# PIC32MK0512MCJ048 device description
Architecture: MIPS; Family: PIC32MK; Series: PIC32MK
Registers are 32-bit, read-write, no defined reset value unless marked. A register's access mark holds for its fields unless they carry their own. Offsets are from the block's base; [hi:lo] are bit positions; 'fields as' and 'values as' point back to an identical list.

## GPIO
Instances: GPIO 0x1f860000 in periph_pb4_std
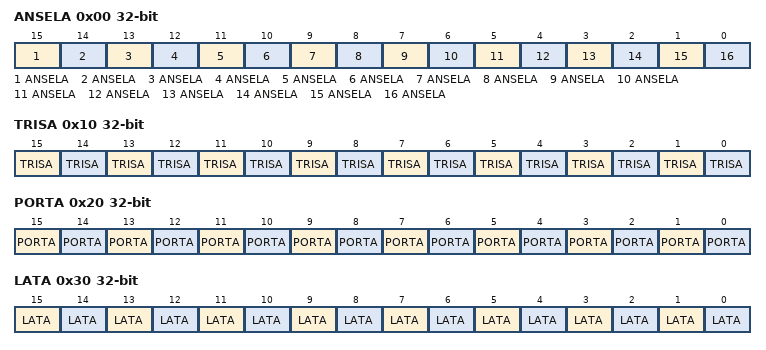
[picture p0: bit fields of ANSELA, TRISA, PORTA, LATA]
0x00 ANSELA
  [15] ANSELA, [14] ANSELA, [13] ANSELA, [12] ANSELA, [11] ANSELA, [10] ANSELA, [9] ANSELA, [8] ANSELA, [7] ANSELA, [6] ANSELA, [5] ANSELA, [4] ANSELA, [3] ANSELA, [2] ANSELA, [1] ANSELA, [0] ANSELA
0x10 TRISA
  [15] TRISA, [14] TRISA, [13] TRISA, [12] TRISA, [11] TRISA, [10] TRISA, [9] TRISA, [8] TRISA, [7] TRISA, [6] TRISA, [5] TRISA, [4] TRISA, [3] TRISA, [2] TRISA, [1] TRISA, [0] TRISA
0x20 PORTA
  [15] PORTA, [14] PORTA, [13] PORTA, [12] PORTA, [11] PORTA, [10] PORTA, [9] PORTA, [8] PORTA, [7] PORTA, [6] PORTA, [5] PORTA, [4] PORTA, [3] PORTA, [2] PORTA, [1] PORTA, [0] PORTA
0x30 LATA
  [15] LATA, [14] LATA, [13] LATA, [12] LATA, [11] LATA, [10] LATA, [9] LATA, [8] LATA, [7] LATA, [6] LATA, [5] LATA, [4] LATA, [3] LATA, [2] LATA, [1] LATA, [0] LATA
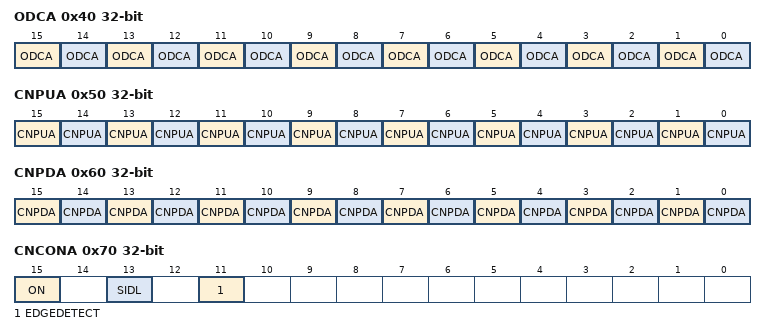
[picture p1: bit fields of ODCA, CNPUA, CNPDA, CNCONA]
0x40 ODCA
  [15] ODCA, [14] ODCA, [13] ODCA, [12] ODCA, [11] ODCA, [10] ODCA, [9] ODCA, [8] ODCA, [7] ODCA, [6] ODCA, [5] ODCA, [4] ODCA, [3] ODCA, [2] ODCA, [1] ODCA, [0] ODCA
0x50 CNPUA
  [15] CNPUA, [14] CNPUA, [13] CNPUA, [12] CNPUA, [11] CNPUA, [10] CNPUA, [9] CNPUA, [8] CNPUA, [7] CNPUA, [6] CNPUA, [5] CNPUA, [4] CNPUA, [3] CNPUA, [2] CNPUA, [1] CNPUA, [0] CNPUA
0x60 CNPDA
  [15] CNPDA, [14] CNPDA, [13] CNPDA, [12] CNPDA, [11] CNPDA, [10] CNPDA, [9] CNPDA, [8] CNPDA, [7] CNPDA, [6] CNPDA, [5] CNPDA, [4] CNPDA, [3] CNPDA, [2] CNPDA, [1] CNPDA, [0] CNPDA
0x70 CNCONA — Change Notice control for PORTx Register
  [15] ON — Change Notice Control ON bit
    1=CN is enabled; 0=CN is disabled
  [13] SIDL
  [11] EDGEDETECT — Change Notification Style bit
    1=Edge Style. Detect edge transitions (CNFx used for CN Event).; 0=Mismatch Style. Detect change from last PORTx read (CNSTATx used for CN Event).
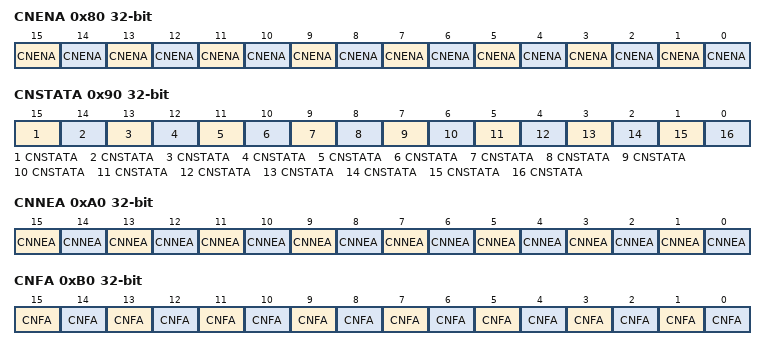
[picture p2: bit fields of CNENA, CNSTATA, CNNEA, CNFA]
0x80 CNENA
  [15] CNENA, [14] CNENA, [13] CNENA, [12] CNENA, [11] CNENA, [10] CNENA, [9] CNENA, [8] CNENA, [7] CNENA, [6] CNENA, [5] CNENA, [4] CNENA, [3] CNENA, [2] CNENA, [1] CNENA, [0] CNENA
0x90 CNSTATA
  [15] CNSTATA, [14] CNSTATA, [13] CNSTATA, [12] CNSTATA, [11] CNSTATA, [10] CNSTATA, [9] CNSTATA, [8] CNSTATA, [7] CNSTATA, [6] CNSTATA, [5] CNSTATA, [4] CNSTATA, [3] CNSTATA, [2] CNSTATA, [1] CNSTATA, [0] CNSTATA
0xA0 CNNEA
  [15] CNNEA, [14] CNNEA, [13] CNNEA, [12] CNNEA, [11] CNNEA, [10] CNNEA, [9] CNNEA, [8] CNNEA, [7] CNNEA, [6] CNNEA, [5] CNNEA, [4] CNNEA, [3] CNNEA, [2] CNNEA, [1] CNNEA, [0] CNNEA
0xB0 CNFA
  [15] CNFA, [14] CNFA, [13] CNFA, [12] CNFA, [11] CNFA, [10] CNFA, [9] CNFA, [8] CNFA, [7] CNFA, [6] CNFA, [5] CNFA, [4] CNFA, [3] CNFA, [2] CNFA, [1] CNFA, [0] CNFA
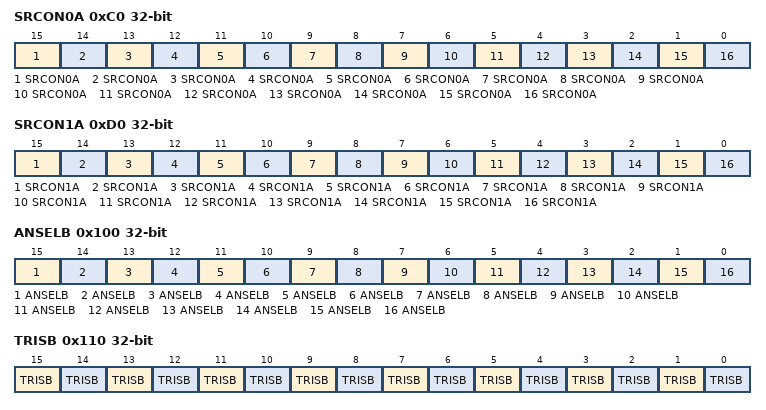
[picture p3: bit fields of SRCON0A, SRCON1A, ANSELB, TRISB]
0xC0 SRCON0A
  [15] SRCON0A, [14] SRCON0A, [13] SRCON0A, [12] SRCON0A, [11] SRCON0A, [10] SRCON0A, [9] SRCON0A, [8] SRCON0A, [7] SRCON0A, [6] SRCON0A, [5] SRCON0A, [4] SRCON0A, [3] SRCON0A, [2] SRCON0A, [1] SRCON0A, [0] SRCON0A
0xD0 SRCON1A
  [15] SRCON1A, [14] SRCON1A, [13] SRCON1A, [12] SRCON1A, [11] SRCON1A, [10] SRCON1A, [9] SRCON1A, [8] SRCON1A, [7] SRCON1A, [6] SRCON1A, [5] SRCON1A, [4] SRCON1A, [3] SRCON1A, [2] SRCON1A, [1] SRCON1A, [0] SRCON1A
0x100 ANSELB
  [15] ANSELB, [14] ANSELB, [13] ANSELB, [12] ANSELB, [11] ANSELB, [10] ANSELB, [9] ANSELB, [8] ANSELB, [7] ANSELB, [6] ANSELB, [5] ANSELB, [4] ANSELB, [3] ANSELB, [2] ANSELB, [1] ANSELB, [0] ANSELB
0x110 TRISB
  [15] TRISB, [14] TRISB, [13] TRISB, [12] TRISB, [11] TRISB, [10] TRISB, [9] TRISB, [8] TRISB, [7] TRISB, [6] TRISB, [5] TRISB, [4] TRISB, [3] TRISB, [2] TRISB, [1] TRISB, [0] TRISB
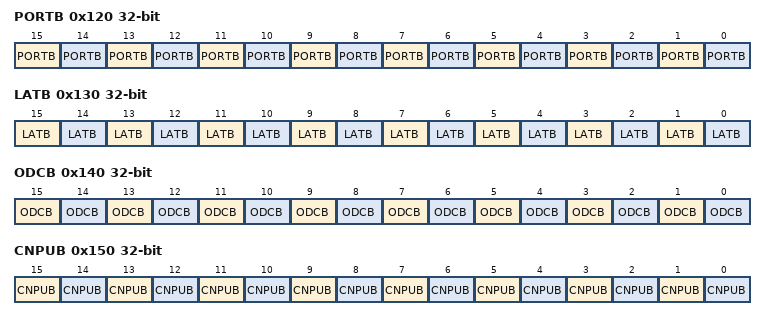
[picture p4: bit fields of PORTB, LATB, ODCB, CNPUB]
0x120 PORTB
  [15] PORTB, [14] PORTB, [13] PORTB, [12] PORTB, [11] PORTB, [10] PORTB, [9] PORTB, [8] PORTB, [7] PORTB, [6] PORTB, [5] PORTB, [4] PORTB, [3] PORTB, [2] PORTB, [1] PORTB, [0] PORTB
0x130 LATB
  [15] LATB, [14] LATB, [13] LATB, [12] LATB, [11] LATB, [10] LATB, [9] LATB, [8] LATB, [7] LATB, [6] LATB, [5] LATB, [4] LATB, [3] LATB, [2] LATB, [1] LATB, [0] LATB
0x140 ODCB
  [15] ODCB, [14] ODCB, [13] ODCB, [12] ODCB, [11] ODCB, [10] ODCB, [9] ODCB, [8] ODCB, [7] ODCB, [6] ODCB, [5] ODCB, [4] ODCB, [3] ODCB, [2] ODCB, [1] ODCB, [0] ODCB
0x150 CNPUB
  [15] CNPUB, [14] CNPUB, [13] CNPUB, [12] CNPUB, [11] CNPUB, [10] CNPUB, [9] CNPUB, [8] CNPUB, [7] CNPUB, [6] CNPUB, [5] CNPUB, [4] CNPUB, [3] CNPUB, [2] CNPUB, [1] CNPUB, [0] CNPUB
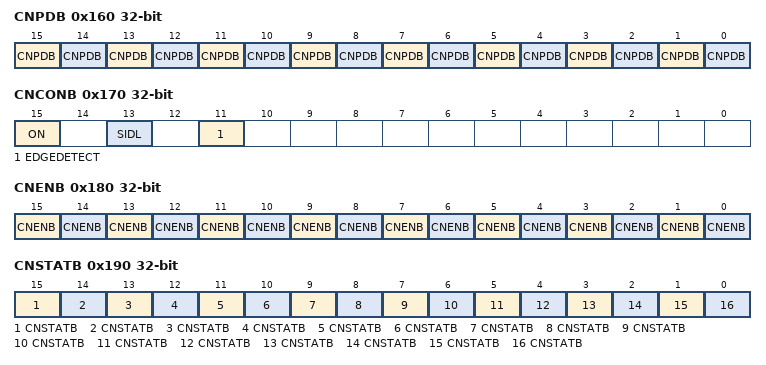
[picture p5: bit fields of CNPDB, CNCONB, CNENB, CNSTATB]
0x160 CNPDB
  [15] CNPDB, [14] CNPDB, [13] CNPDB, [12] CNPDB, [11] CNPDB, [10] CNPDB, [9] CNPDB, [8] CNPDB, [7] CNPDB, [6] CNPDB, [5] CNPDB, [4] CNPDB, [3] CNPDB, [2] CNPDB, [1] CNPDB, [0] CNPDB
0x170 CNCONB — Change Notice control for PORTx Register
  fields as CNCONA
0x180 CNENB
  [15] CNENB, [14] CNENB, [13] CNENB, [12] CNENB, [11] CNENB, [10] CNENB, [9] CNENB, [8] CNENB, [7] CNENB, [6] CNENB, [5] CNENB, [4] CNENB, [3] CNENB, [2] CNENB, [1] CNENB, [0] CNENB
0x190 CNSTATB
  [15] CNSTATB, [14] CNSTATB, [13] CNSTATB, [12] CNSTATB, [11] CNSTATB, [10] CNSTATB, [9] CNSTATB, [8] CNSTATB, [7] CNSTATB, [6] CNSTATB, [5] CNSTATB, [4] CNSTATB, [3] CNSTATB, [2] CNSTATB, [1] CNSTATB, [0] CNSTATB
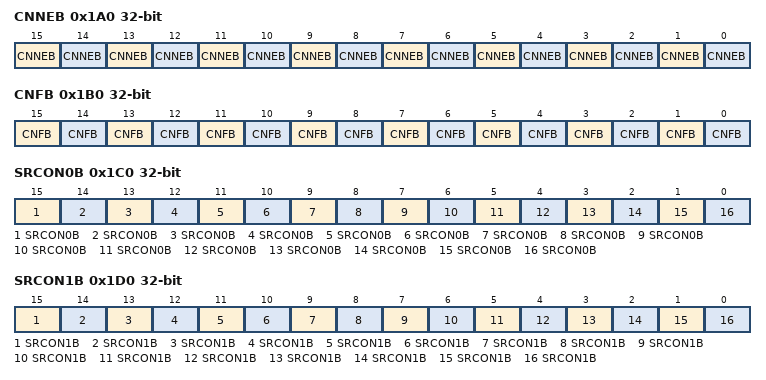
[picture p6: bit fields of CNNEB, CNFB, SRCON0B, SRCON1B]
0x1A0 CNNEB
  [15] CNNEB, [14] CNNEB, [13] CNNEB, [12] CNNEB, [11] CNNEB, [10] CNNEB, [9] CNNEB, [8] CNNEB, [7] CNNEB, [6] CNNEB, [5] CNNEB, [4] CNNEB, [3] CNNEB, [2] CNNEB, [1] CNNEB, [0] CNNEB
0x1B0 CNFB
  [15] CNFB, [14] CNFB, [13] CNFB, [12] CNFB, [11] CNFB, [10] CNFB, [9] CNFB, [8] CNFB, [7] CNFB, [6] CNFB, [5] CNFB, [4] CNFB, [3] CNFB, [2] CNFB, [1] CNFB, [0] CNFB
0x1C0 SRCON0B
  [15] SRCON0B, [14] SRCON0B, [13] SRCON0B, [12] SRCON0B, [11] SRCON0B, [10] SRCON0B, [9] SRCON0B, [8] SRCON0B, [7] SRCON0B, [6] SRCON0B, [5] SRCON0B, [4] SRCON0B, [3] SRCON0B, [2] SRCON0B, [1] SRCON0B, [0] SRCON0B
0x1D0 SRCON1B
  [15] SRCON1B, [14] SRCON1B, [13] SRCON1B, [12] SRCON1B, [11] SRCON1B, [10] SRCON1B, [9] SRCON1B, [8] SRCON1B, [7] SRCON1B, [6] SRCON1B, [5] SRCON1B, [4] SRCON1B, [3] SRCON1B, [2] SRCON1B, [1] SRCON1B, [0] SRCON1B
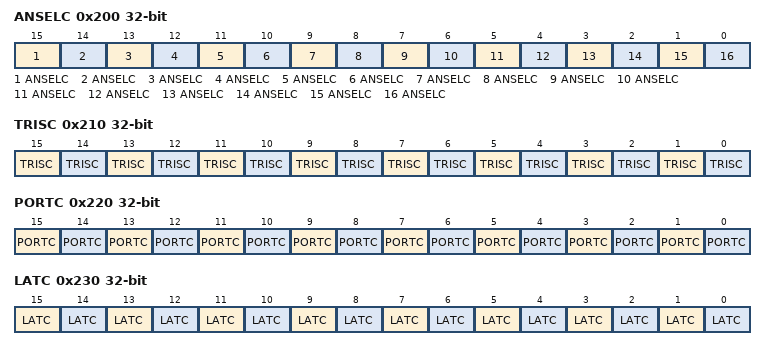
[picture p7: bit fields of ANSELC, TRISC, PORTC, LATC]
0x200 ANSELC
  [15] ANSELC, [14] ANSELC, [13] ANSELC, [12] ANSELC, [11] ANSELC, [10] ANSELC, [9] ANSELC, [8] ANSELC, [7] ANSELC, [6] ANSELC, [5] ANSELC, [4] ANSELC, [3] ANSELC, [2] ANSELC, [1] ANSELC, [0] ANSELC
0x210 TRISC
  [15] TRISC, [14] TRISC, [13] TRISC, [12] TRISC, [11] TRISC, [10] TRISC, [9] TRISC, [8] TRISC, [7] TRISC, [6] TRISC, [5] TRISC, [4] TRISC, [3] TRISC, [2] TRISC, [1] TRISC, [0] TRISC
0x220 PORTC
  [15] PORTC, [14] PORTC, [13] PORTC, [12] PORTC, [11] PORTC, [10] PORTC, [9] PORTC, [8] PORTC, [7] PORTC, [6] PORTC, [5] PORTC, [4] PORTC, [3] PORTC, [2] PORTC, [1] PORTC, [0] PORTC
0x230 LATC
  [15] LATC, [14] LATC, [13] LATC, [12] LATC, [11] LATC, [10] LATC, [9] LATC, [8] LATC, [7] LATC, [6] LATC, [5] LATC, [4] LATC, [3] LATC, [2] LATC, [1] LATC, [0] LATC
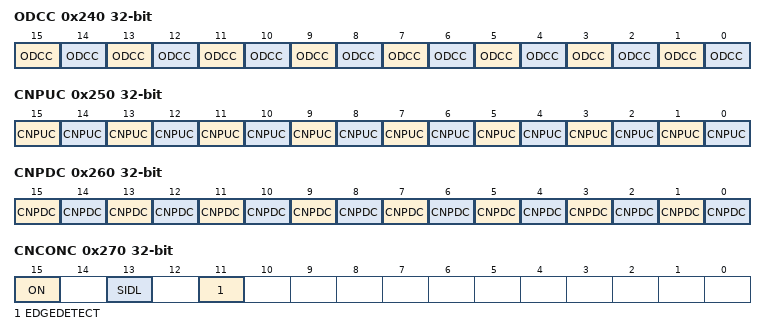
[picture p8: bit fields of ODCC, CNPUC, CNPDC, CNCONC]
0x240 ODCC
  [15] ODCC, [14] ODCC, [13] ODCC, [12] ODCC, [11] ODCC, [10] ODCC, [9] ODCC, [8] ODCC, [7] ODCC, [6] ODCC, [5] ODCC, [4] ODCC, [3] ODCC, [2] ODCC, [1] ODCC, [0] ODCC
0x250 CNPUC
  [15] CNPUC, [14] CNPUC, [13] CNPUC, [12] CNPUC, [11] CNPUC, [10] CNPUC, [9] CNPUC, [8] CNPUC, [7] CNPUC, [6] CNPUC, [5] CNPUC, [4] CNPUC, [3] CNPUC, [2] CNPUC, [1] CNPUC, [0] CNPUC
0x260 CNPDC
  [15] CNPDC, [14] CNPDC, [13] CNPDC, [12] CNPDC, [11] CNPDC, [10] CNPDC, [9] CNPDC, [8] CNPDC, [7] CNPDC, [6] CNPDC, [5] CNPDC, [4] CNPDC, [3] CNPDC, [2] CNPDC, [1] CNPDC, [0] CNPDC
0x270 CNCONC — Change Notice control for PORTx Register
  fields as CNCONA
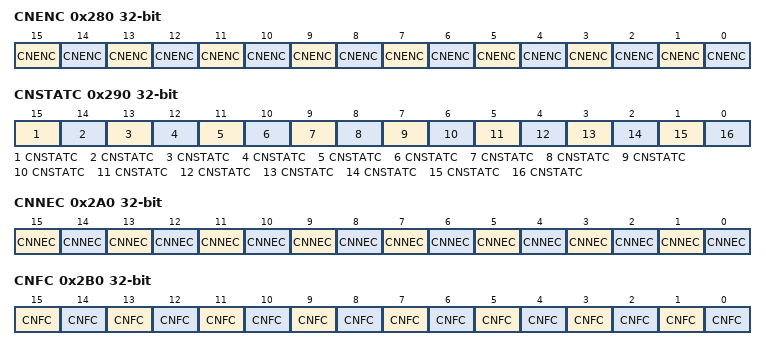
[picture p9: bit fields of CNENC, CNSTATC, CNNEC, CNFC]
0x280 CNENC
  [15] CNENC, [14] CNENC, [13] CNENC, [12] CNENC, [11] CNENC, [10] CNENC, [9] CNENC, [8] CNENC, [7] CNENC, [6] CNENC, [5] CNENC, [4] CNENC, [3] CNENC, [2] CNENC, [1] CNENC, [0] CNENC
0x290 CNSTATC
  [15] CNSTATC, [14] CNSTATC, [13] CNSTATC, [12] CNSTATC, [11] CNSTATC, [10] CNSTATC, [9] CNSTATC, [8] CNSTATC, [7] CNSTATC, [6] CNSTATC, [5] CNSTATC, [4] CNSTATC, [3] CNSTATC, [2] CNSTATC, [1] CNSTATC, [0] CNSTATC
0x2A0 CNNEC
  [15] CNNEC, [14] CNNEC, [13] CNNEC, [12] CNNEC, [11] CNNEC, [10] CNNEC, [9] CNNEC, [8] CNNEC, [7] CNNEC, [6] CNNEC, [5] CNNEC, [4] CNNEC, [3] CNNEC, [2] CNNEC, [1] CNNEC, [0] CNNEC
0x2B0 CNFC
  [15] CNFC, [14] CNFC, [13] CNFC, [12] CNFC, [11] CNFC, [10] CNFC, [9] CNFC, [8] CNFC, [7] CNFC, [6] CNFC, [5] CNFC, [4] CNFC, [3] CNFC, [2] CNFC, [1] CNFC, [0] CNFC
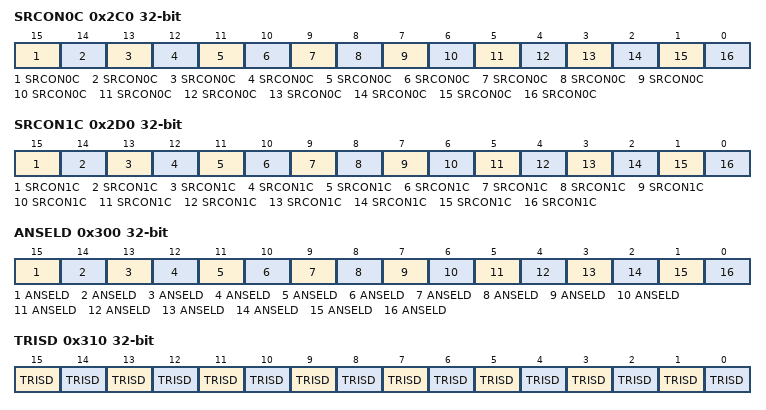
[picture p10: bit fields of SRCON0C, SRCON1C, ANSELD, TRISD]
0x2C0 SRCON0C
  [15] SRCON0C, [14] SRCON0C, [13] SRCON0C, [12] SRCON0C, [11] SRCON0C, [10] SRCON0C, [9] SRCON0C, [8] SRCON0C, [7] SRCON0C, [6] SRCON0C, [5] SRCON0C, [4] SRCON0C, [3] SRCON0C, [2] SRCON0C, [1] SRCON0C, [0] SRCON0C
0x2D0 SRCON1C
  [15] SRCON1C, [14] SRCON1C, [13] SRCON1C, [12] SRCON1C, [11] SRCON1C, [10] SRCON1C, [9] SRCON1C, [8] SRCON1C, [7] SRCON1C, [6] SRCON1C, [5] SRCON1C, [4] SRCON1C, [3] SRCON1C, [2] SRCON1C, [1] SRCON1C, [0] SRCON1C
0x300 ANSELD
  [15] ANSELD, [14] ANSELD, [13] ANSELD, [12] ANSELD, [11] ANSELD, [10] ANSELD, [9] ANSELD, [8] ANSELD, [7] ANSELD, [6] ANSELD, [5] ANSELD, [4] ANSELD, [3] ANSELD, [2] ANSELD, [1] ANSELD, [0] ANSELD
0x310 TRISD
  [15] TRISD, [14] TRISD, [13] TRISD, [12] TRISD, [11] TRISD, [10] TRISD, [9] TRISD, [8] TRISD, [7] TRISD, [6] TRISD, [5] TRISD, [4] TRISD, [3] TRISD, [2] TRISD, [1] TRISD, [0] TRISD
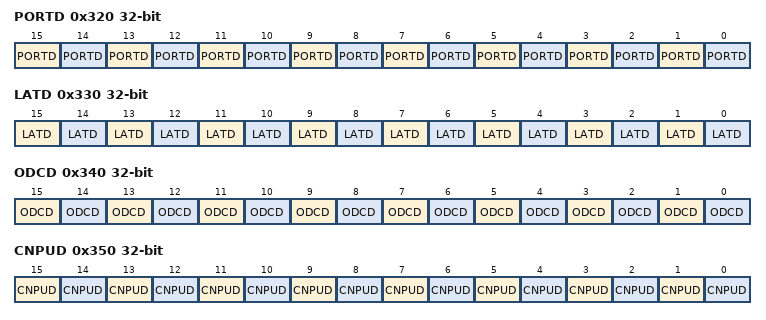
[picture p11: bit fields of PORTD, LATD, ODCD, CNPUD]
0x320 PORTD
  [15] PORTD, [14] PORTD, [13] PORTD, [12] PORTD, [11] PORTD, [10] PORTD, [9] PORTD, [8] PORTD, [7] PORTD, [6] PORTD, [5] PORTD, [4] PORTD, [3] PORTD, [2] PORTD, [1] PORTD, [0] PORTD
0x330 LATD
  [15] LATD, [14] LATD, [13] LATD, [12] LATD, [11] LATD, [10] LATD, [9] LATD, [8] LATD, [7] LATD, [6] LATD, [5] LATD, [4] LATD, [3] LATD, [2] LATD, [1] LATD, [0] LATD
0x340 ODCD
  [15] ODCD, [14] ODCD, [13] ODCD, [12] ODCD, [11] ODCD, [10] ODCD, [9] ODCD, [8] ODCD, [7] ODCD, [6] ODCD, [5] ODCD, [4] ODCD, [3] ODCD, [2] ODCD, [1] ODCD, [0] ODCD
0x350 CNPUD
  [15] CNPUD, [14] CNPUD, [13] CNPUD, [12] CNPUD, [11] CNPUD, [10] CNPUD, [9] CNPUD, [8] CNPUD, [7] CNPUD, [6] CNPUD, [5] CNPUD, [4] CNPUD, [3] CNPUD, [2] CNPUD, [1] CNPUD, [0] CNPUD
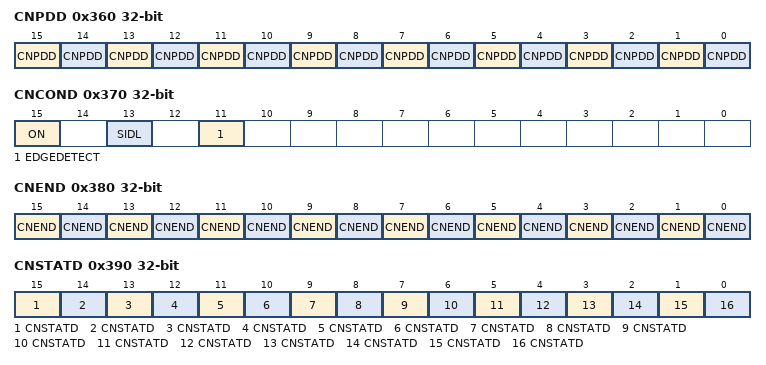
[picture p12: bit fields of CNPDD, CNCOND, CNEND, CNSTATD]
0x360 CNPDD
  [15] CNPDD, [14] CNPDD, [13] CNPDD, [12] CNPDD, [11] CNPDD, [10] CNPDD, [9] CNPDD, [8] CNPDD, [7] CNPDD, [6] CNPDD, [5] CNPDD, [4] CNPDD, [3] CNPDD, [2] CNPDD, [1] CNPDD, [0] CNPDD
0x370 CNCOND — Change Notice control for PORTx Register
  fields as CNCONA
0x380 CNEND
  [15] CNEND, [14] CNEND, [13] CNEND, [12] CNEND, [11] CNEND, [10] CNEND, [9] CNEND, [8] CNEND, [7] CNEND, [6] CNEND, [5] CNEND, [4] CNEND, [3] CNEND, [2] CNEND, [1] CNEND, [0] CNEND
0x390 CNSTATD
  [15] CNSTATD, [14] CNSTATD, [13] CNSTATD, [12] CNSTATD, [11] CNSTATD, [10] CNSTATD, [9] CNSTATD, [8] CNSTATD, [7] CNSTATD, [6] CNSTATD, [5] CNSTATD, [4] CNSTATD, [3] CNSTATD, [2] CNSTATD, [1] CNSTATD, [0] CNSTATD
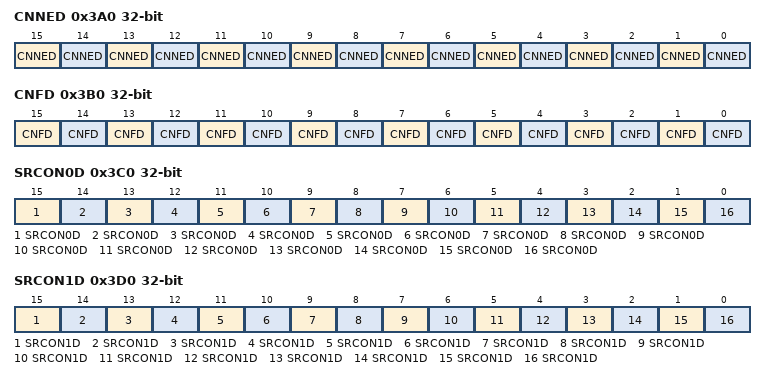
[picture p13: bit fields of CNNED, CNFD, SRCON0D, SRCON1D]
0x3A0 CNNED
  [15] CNNED, [14] CNNED, [13] CNNED, [12] CNNED, [11] CNNED, [10] CNNED, [9] CNNED, [8] CNNED, [7] CNNED, [6] CNNED, [5] CNNED, [4] CNNED, [3] CNNED, [2] CNNED, [1] CNNED, [0] CNNED
0x3B0 CNFD
  [15] CNFD, [14] CNFD, [13] CNFD, [12] CNFD, [11] CNFD, [10] CNFD, [9] CNFD, [8] CNFD, [7] CNFD, [6] CNFD, [5] CNFD, [4] CNFD, [3] CNFD, [2] CNFD, [1] CNFD, [0] CNFD
0x3C0 SRCON0D
  [15] SRCON0D, [14] SRCON0D, [13] SRCON0D, [12] SRCON0D, [11] SRCON0D, [10] SRCON0D, [9] SRCON0D, [8] SRCON0D, [7] SRCON0D, [6] SRCON0D, [5] SRCON0D, [4] SRCON0D, [3] SRCON0D, [2] SRCON0D, [1] SRCON0D, [0] SRCON0D
0x3D0 SRCON1D
  [15] SRCON1D, [14] SRCON1D, [13] SRCON1D, [12] SRCON1D, [11] SRCON1D, [10] SRCON1D, [9] SRCON1D, [8] SRCON1D, [7] SRCON1D, [6] SRCON1D, [5] SRCON1D, [4] SRCON1D, [3] SRCON1D, [2] SRCON1D, [1] SRCON1D, [0] SRCON1D
